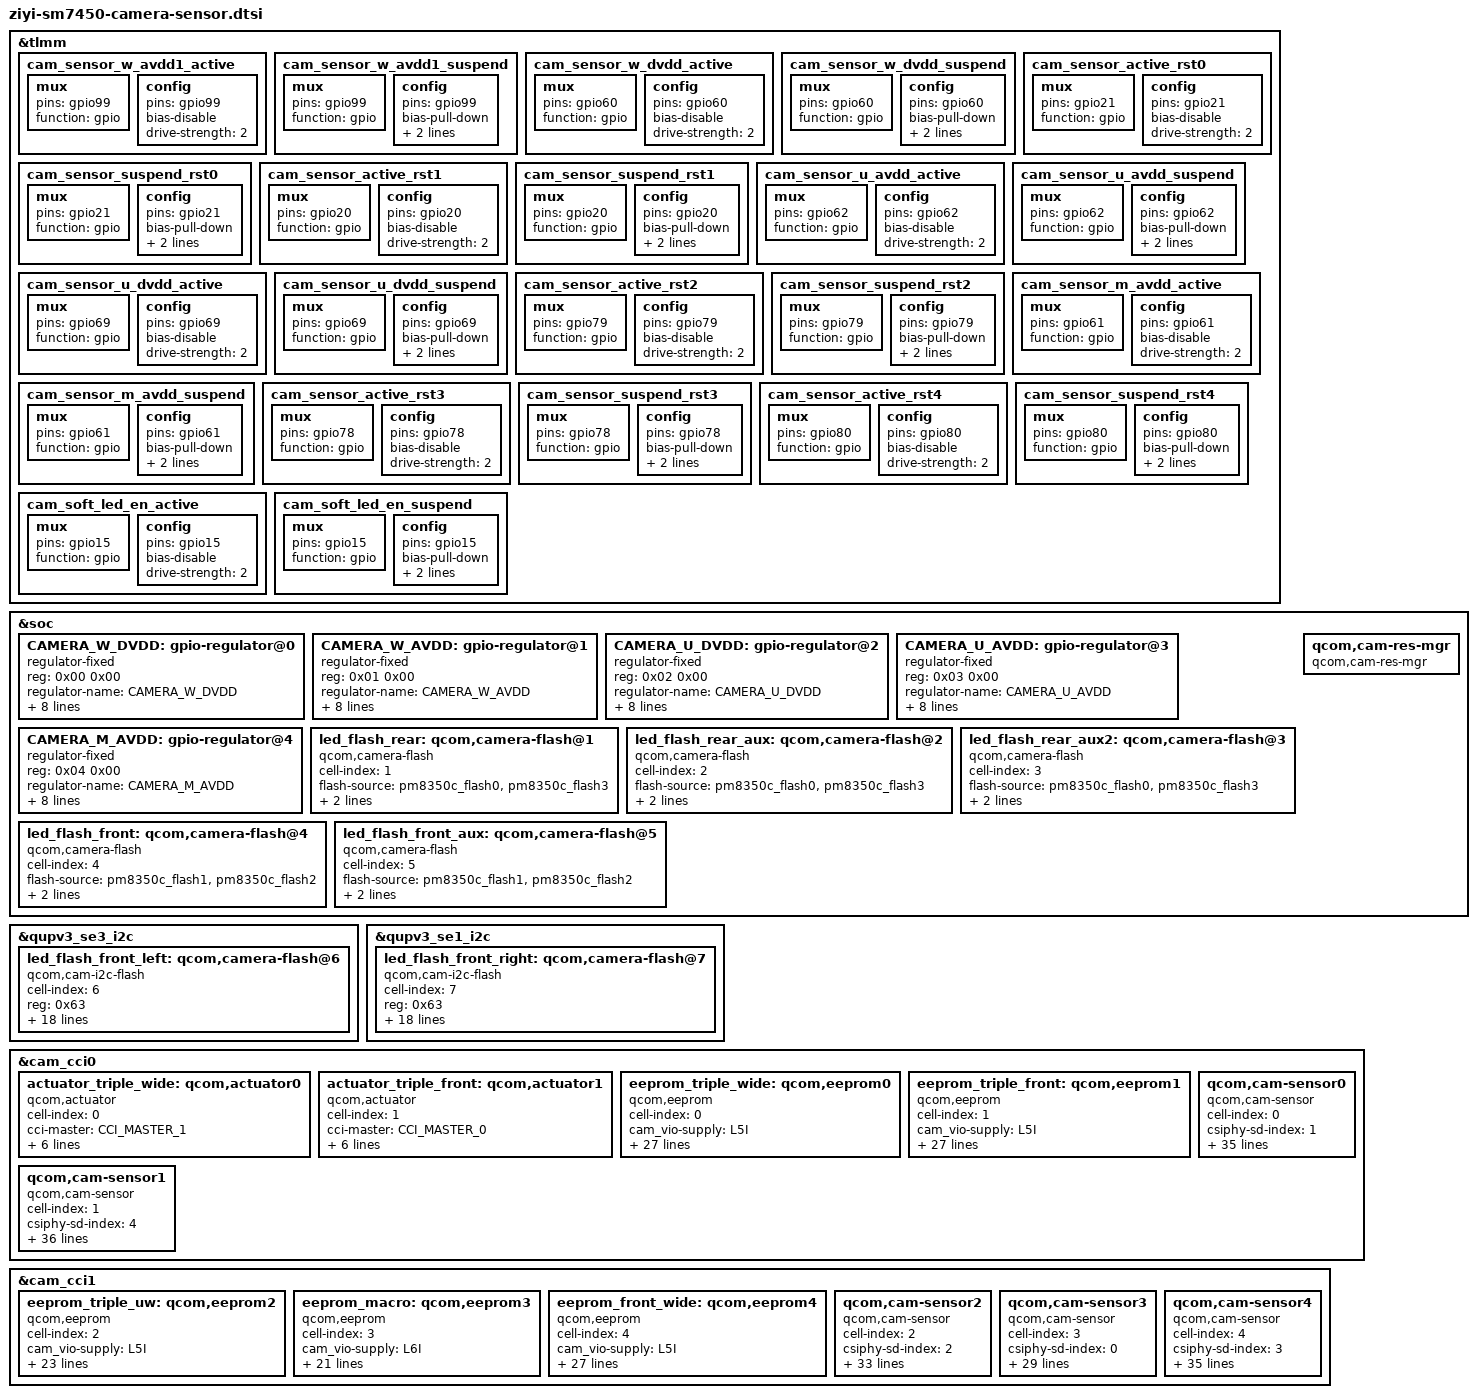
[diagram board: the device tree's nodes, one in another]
#include <dt-bindings/clock/qcom,camcc-diwali.h>
#include <dt-bindings/msm-camera.h>

&tlmm {
	//wide avdd
	cam_sensor_w_avdd1_active: cam_sensor_w_avdd1_active {
		/* SENSOR WIDE DVDD ENABLE */
		mux {
			pins = "gpio99";
			function = "gpio";
		};

		config {
			pins = "gpio99";
			bias-disable; /* No PULL */
			drive-strength = <2>; /* 2 MA */
		};
	};

	cam_sensor_w_avdd1_suspend: cam_sensor_w_avdd1_suspend {
		/* SENSOR WIDE DVDD DISABLE */
		mux {
			pins = "gpio99";
			function = "gpio";
		};

		config {
			pins = "gpio99";
			bias-pull-down; /* PULL DOWN */
			drive-strength = <2>; /* 2 MA */
			output-low;
		};
	};

	//wide dvdd
	cam_sensor_w_dvdd_active: cam_sensor_w_dvdd_active {
		/* SENSOR WIDE DVDD ENABLE */
		mux {
			pins = "gpio60";
			function = "gpio";
		};

		config {
			pins = "gpio60";
			bias-disable; /* No PULL */
			drive-strength = <2>; /* 2 MA */
		};
	};

	cam_sensor_w_dvdd_suspend: cam_sensor_w_dvdd_suspend {
		/* SENSOR WIDE DVDD DISABLE */
		mux {
			pins = "gpio60";
			function = "gpio";
		};

		config {
			pins = "gpio60";
			bias-pull-down; /* PULL DOWN */
			drive-strength = <2>; /* 2 MA */
			output-low;
		};
	};

	//wide reset
	cam_sensor_active_rst0: cam_sensor_active_rst0 {
		/* RESET FRONT */
		mux {
			pins = "gpio21";
			function = "gpio";
		};

		config {
			pins = "gpio21";
			bias-disable; /* No PULL */
			drive-strength = <2>; /* 2 MA */
		};
	};

	cam_sensor_suspend_rst0: cam_sensor_suspend_rst0 {
		/* RESET FRONT */
		mux {
			pins = "gpio21";
			function = "gpio";
		};

		config {
			pins = "gpio21";
			bias-pull-down; /* PULL DOWN */
			drive-strength = <2>; /* 2 MA */
			output-low;
		};
	};

	//front reset
	cam_sensor_active_rst1: cam_sensor_active_rst1 {
		/* RESET FRONT */
		mux {
			pins = "gpio20";
			function = "gpio";
		};

		config {
			pins = "gpio20";
			bias-disable; /* No PULL */
			drive-strength = <2>; /* 2 MA */
		};
	};

	cam_sensor_suspend_rst1: cam_sensor_suspend_rst1 {
		/* RESET FRONT */
		mux {
			pins = "gpio20";
			function = "gpio";
		};

		config {
			pins = "gpio20";
			bias-pull-down; /* PULL DOWN */
			drive-strength = <2>; /* 2 MA */
			output-low;
		};
	};

	//ultra avdd
	cam_sensor_u_avdd_active: cam_sensor_u_avdd_active {
		/* SENSOR ULTRA AVDD ENABLE */
		mux {
			pins = "gpio62";
			function = "gpio";
		};

		config {
			pins = "gpio62";
			bias-disable; /* No PULL */
			drive-strength = <2>; /* 2 MA */
		};
	};

	cam_sensor_u_avdd_suspend: cam_sensor_u_avdd_suspend {
		/* SENSOR ULTRA AVDD DISABLE */
		mux {
			pins = "gpio62";
			function = "gpio";
		};

		config {
			pins = "gpio62";
			bias-pull-down; /* PULL DOWN */
			drive-strength = <2>; /* 2 MA */
			output-low;
		};
	};

	//ultra dvdd
	cam_sensor_u_dvdd_active: cam_sensor_u_dvdd_active {
		/* SENSOR ULTRA DVDD ENABLE */
		mux {
			pins = "gpio69";
			function = "gpio";
		};

		config {
			pins = "gpio69";
			bias-disable; /* No PULL */
			drive-strength = <2>; /* 2 MA */
		};
	};

	cam_sensor_u_dvdd_suspend: cam_sensor_u_dvdd_suspend {
		/* SENSOR ULTRA DVDD DISABLE */
		mux {
			pins = "gpio69";
			function = "gpio";
		};

		config {
			pins = "gpio69";
			bias-pull-down; /* PULL DOWN */
			drive-strength = <2>; /* 2 MA */
			output-low;
		};
	};

	//ultra reset
	cam_sensor_active_rst2: cam_sensor_active_rst2 {
		/* RESET ULTRA */
		mux {
			pins = "gpio79";
			function = "gpio";
		};

		config {
			pins = "gpio79";
			bias-disable; /* No PULL */
			drive-strength = <2>; /* 2 MA */
		};
	};

	cam_sensor_suspend_rst2: cam_sensor_suspend_rst2 {
		/* RESET ULTRA */
		mux {
			pins = "gpio79";
			function = "gpio";
		};

		config {
			pins = "gpio79";
			bias-pull-down; /* PULL DOWN */
			drive-strength = <2>; /* 2 MA */
			output-low;
		};
	};

	//macro avdd
	cam_sensor_m_avdd_active: cam_sensor_m_avdd_active {
		/* SENSOR MACRO AVDD ENABLE */
		mux {
			pins = "gpio61";
			function = "gpio";
		};

		config {
			pins = "gpio61";
			bias-disable; /* No PULL */
			drive-strength = <2>; /* 2 MA */
		};
	};

	cam_sensor_m_avdd_suspend: cam_sensor_m_avdd_suspend {
		/* SENSOR MACRO AVDD DISABLE */
		mux {
			pins = "gpio61";
			function = "gpio";
		};

		config {
			pins = "gpio61";
			bias-pull-down; /* PULL DOWN */
			drive-strength = <2>; /* 2 MA */
			output-low;
		};
	};

	//macro reset
	cam_sensor_active_rst3: cam_sensor_active_rst3 {
		/* RESET MACRO */
		mux {
			pins = "gpio78";
			function = "gpio";
		};

		config {
			pins = "gpio78";
			bias-disable; /* No PULL */
			drive-strength = <2>; /* 2 MA */
		};
	};

	cam_sensor_suspend_rst3: cam_sensor_suspend_rst3 {
		/* RESET MACRO */
		mux {
			pins = "gpio78";
			function = "gpio";
		};

		config {
			pins = "gpio78";
			bias-pull-down; /* PULL DOWN */
			drive-strength = <2>; /* 2 MA */
			output-low;
		};
	};


	//front ultra reset
	cam_sensor_active_rst4: cam_sensor_active_rst4 {
		/* RESET FRONT ULTRA*/
		mux {
			pins = "gpio80";
			function = "gpio";
		};

		config {
			pins = "gpio80";
			bias-disable; /* No PULL */
			drive-strength = <2>; /* 2 MA */
		};
	};

	cam_sensor_suspend_rst4: cam_sensor_suspend_rst4 {
		/* RESET FRONT ULTRA*/
		mux {
			pins = "gpio80";
			function = "gpio";
		};

		config {
			pins = "gpio80";
			bias-pull-down; /* PULL DOWN */
			drive-strength = <2>; /* 2 MA */
			output-low;
		};
	};

	//soft flash control
	cam_soft_led_en_active: cam_soft_led_en_active {
		mux {
			pins = "gpio15";
			function = "gpio";
		};

		config {
			pins = "gpio15";
			bias-disable; /* No PULL */
			drive-strength = <2>; /* 2 MA */
		};
	};
	cam_soft_led_en_suspend: cam_soft_led_en_suspend {
		mux {
			pins = "gpio15";
			function = "gpio";
		};

		config {
			pins = "gpio15";
			bias-pull-down; /* PULL DOWN */
			drive-strength = <2>; /* 2 MA */
			output-low;
		};
	};
};


&soc {
	CAMERA_W_DVDD: gpio-regulator@0 {
		compatible = "regulator-fixed";
		reg = <0x00 0x00>;
		regulator-name = "CAMERA_W_DVDD";
		regulator-min-microvolt = <1100000>;
		regulator-max-microvolt = <1100000>;
		regulator-enable-ramp-delay = <100>;
		enable-active-high;
		gpio = <&tlmm 60 0>;
		pinctrl-names = "default", "sleep";
		pinctrl-0 = <&cam_sensor_w_dvdd_active &cam_sensor_w_dvdd_suspend>;
		vin-supply = <&S8B>;
	};

	CAMERA_W_AVDD: gpio-regulator@1 {
		compatible = "regulator-fixed";
		reg = <0x01 0x00>;
		regulator-name = "CAMERA_W_AVDD";
		regulator-min-microvolt = <2800000>;
		regulator-max-microvolt = <2800000>;
		regulator-enable-ramp-delay = <100>;
		enable-active-high;
		gpio = <&tlmm 99 0>;
		pinctrl-names = "default", "sleep";
		pinctrl-0 = <&cam_sensor_w_avdd1_active &cam_sensor_w_avdd1_suspend>;
		vin-supply = <&BOB>;
	};

	CAMERA_U_DVDD: gpio-regulator@2 {
		compatible = "regulator-fixed";
		reg = <0x02 0x00>;
		regulator-name = "CAMERA_U_DVDD";
		regulator-min-microvolt = <1050000>;
		regulator-max-microvolt = <1050000>;
		regulator-enable-ramp-delay = <100>;
		enable-active-high;
		gpio = <&tlmm 69 0>;
		pinctrl-names = "default", "sleep";
		pinctrl-0 = <&cam_sensor_u_dvdd_active &cam_sensor_u_dvdd_suspend>;
		vin-supply = <&S8B>;
	};

	CAMERA_U_AVDD: gpio-regulator@3 {
		compatible = "regulator-fixed";
		reg = <0x03 0x00>;
		regulator-name = "CAMERA_U_AVDD";
		regulator-min-microvolt = <2800000>;
		regulator-max-microvolt = <2800000>;
		regulator-enable-ramp-delay = <100>;
		enable-active-high;
		gpio = <&tlmm 62 0>;
		pinctrl-names = "default", "sleep";
		pinctrl-0 = <&cam_sensor_u_avdd_active &cam_sensor_u_avdd_suspend>;
		vin-supply = <&BOB>;
	};

	CAMERA_M_AVDD: gpio-regulator@4 {
		compatible = "regulator-fixed";
		reg = <0x04 0x00>;
		regulator-name = "CAMERA_M_AVDD";
		regulator-min-microvolt = <2800000>;
		regulator-max-microvolt = <2800000>;
		regulator-enable-ramp-delay = <100>;
		enable-active-high;
		gpio = <&tlmm 61 0>;
		pinctrl-names = "default", "sleep";
		pinctrl-0 = <&cam_sensor_m_avdd_active &cam_sensor_m_avdd_suspend>;
		vin-supply = <&BOB>;
	};

	led_flash_rear: qcom,camera-flash@1 {
		cell-index = <1>;
		compatible = "qcom,camera-flash";
		flash-source = <&pm8350c_flash0 &pm8350c_flash3>;
		torch-source = <&pm8350c_torch0 &pm8350c_torch3>;
		switch-source = <&pm8350c_switch0>;
		status = "ok";
	};

	led_flash_rear_aux: qcom,camera-flash@2 {
		cell-index = <2>;
		compatible = "qcom,camera-flash";
		flash-source = <&pm8350c_flash0 &pm8350c_flash3>;
		torch-source = <&pm8350c_torch0 &pm8350c_torch3>;
		switch-source = <&pm8350c_switch0>;
		status = "ok";
	};

	led_flash_rear_aux2: qcom,camera-flash@3 {
		cell-index = <3>;
		compatible = "qcom,camera-flash";
		flash-source = <&pm8350c_flash0 &pm8350c_flash3>;
		torch-source = <&pm8350c_torch0 &pm8350c_torch3>;
		switch-source = <&pm8350c_switch0>;
		status = "ok";
	};

	led_flash_front: qcom,camera-flash@4 {
		cell-index = <4>;
		compatible = "qcom,camera-flash";
		flash-source = <&pm8350c_flash1 &pm8350c_flash2>;
		torch-source = <&pm8350c_torch1 &pm8350c_torch2>;
		switch-source = <&pm8350c_switch1>;
		status = "ok";
	};

	led_flash_front_aux: qcom,camera-flash@5 {
		cell-index = <5>;
		compatible = "qcom,camera-flash";
		flash-source = <&pm8350c_flash1 &pm8350c_flash2>;
		torch-source = <&pm8350c_torch1 &pm8350c_torch2>;
		switch-source = <&pm8350c_switch1>;
		status = "ok";
	};

	qcom,cam-res-mgr {
		compatible = "qcom,cam-res-mgr";
		status = "ok";
	};
};

&qupv3_se3_i2c {
	status = "ok";
	led_flash_front_left: qcom,camera-flash@6 {
		cell-index = <6>;
		reg = <0x63>;
		qcom,slave-id = <0x63>;
		compatible = "qcom,cam-i2c-flash";
		qcom,flash-name = "cam-i2c-flash";
		flash-type = <1>;
		cam_vio-supply = <&L18B>;
		cam_bob-supply = <&BOB>;
		regulator-names = "cam_vio","cam_bob";
		rgltr-cntrl-support;
		rgltr-min-voltage = <1800000 3008000>;
		rgltr-max-voltage = <1800000 3960000>;
		rgltr-load-current = <1067000 7840000>;
		qcom,gpio-no-mux = <0>;
		pinctrl-names = "cam_default", "cam_suspend";
		pinctrl-0 = <&cam_soft_led_en_active>;
		pinctrl-1 = <&cam_soft_led_en_suspend>;
		gpios = <&tlmm 15 0>;
		gpio-custom1 = <0>;
		gpio-req-tbl-num = <0>;
		gpio-req-tbl-flags = <0>;
		gpio-req-tbl-label = "CUSTOM_GPIO1";
		status = "ok";
	};
};

&qupv3_se1_i2c {
	status = "ok";
	led_flash_front_right: qcom,camera-flash@7 {
		cell-index = <7>;
		reg = <0x63>;
		qcom,slave-id = <0x63>;
		compatible = "qcom,cam-i2c-flash";
		qcom,flash-name = "cam-i2c-flash";
		flash-type = <1>;
		cam_vio-supply = <&L18B>;
		cam_bob-supply = <&BOB>;
		regulator-names = "cam_vio","cam_bob";
		rgltr-cntrl-support;
		rgltr-min-voltage = <1800000 3008000>;
		rgltr-max-voltage = <1800000 3960000>;
		rgltr-load-current = <1067000 7840000>;
		qcom,gpio-no-mux = <0>;
		pinctrl-names = "cam_default", "cam_suspend";
		pinctrl-0 = <&cam_soft_led_en_active>;
		pinctrl-1 = <&cam_soft_led_en_suspend>;
		gpios = <&tlmm 15 0>;
		gpio-custom1 = <0>;
		gpio-req-tbl-num = <0>;
		gpio-req-tbl-flags = <0>;
		gpio-req-tbl-label = "CUSTOM_GPIO1";
		status = "ok";
	};
};

&cam_cci0 {
	actuator_triple_wide: qcom,actuator0 {
		cell-index = <0>;
		compatible = "qcom,actuator";
		cci-master = <CCI_MASTER_1>;
		cam_vaf-supply = <&L6C>;
		regulator-names = "cam_vaf";
		rgltr-cntrl-support;
		rgltr-min-voltage = <2800000>;
		rgltr-max-voltage = <2800000>;
		rgltr-load-current = <300000>;
	};

	actuator_triple_front: qcom,actuator1 {
		cell-index = <1>;
		compatible = "qcom,actuator";
		cci-master = <CCI_MASTER_0>;
		cam_vaf-supply = <&L9C>;
		regulator-names = "cam_vaf";
		rgltr-cntrl-support;
		rgltr-min-voltage = <2800000>;
		rgltr-max-voltage = <2800000>;
		rgltr-load-current = <120000>;
	};

	eeprom_triple_wide: qcom,eeprom0 {
		cell-index = <0>;
		compatible = "qcom,eeprom";
		cam_vio-supply = <&L5I>;
		cam_vana-supply = <&CAMERA_W_AVDD>;
		cam_vdig-supply = <&CAMERA_W_DVDD>;
		cam_vaf-supply = <&L6C>;
		cam_clk-supply = <&cam_cc_titan_top_gdsc>;
		regulator-names = "cam_vio", "cam_vana", "cam_vdig",
			"cam_clk", "cam_vaf";
		rgltr-cntrl-support;
		rgltr-min-voltage = <1800000 2704000 1100000 2800000 0>;
		rgltr-max-voltage = <1800000 2896000 1100000 2800000 0>;
		rgltr-load-current = <3500 164100 1251000 300000 0>;
		gpio-no-mux = <0>;
		pinctrl-names = "cam_default", "cam_suspend";
		pinctrl-0 = <&cam_sensor_mclk1_active
				 &cam_sensor_active_rst0>;
		pinctrl-1 = <&cam_sensor_mclk1_suspend
				 &cam_sensor_suspend_rst0>;
		gpios = <&tlmm 65 0>,
			<&tlmm 21 0>;
		gpio-reset = <1>;
		gpio-req-tbl-num = <0 1>;
		gpio-req-tbl-flags = <1 0>;
		gpio-req-tbl-label = "CAMIF_MCLK1",
					"CAM_RESET0";
		cci-master = <CCI_MASTER_1>;
		clocks = <&camcc CAM_CC_MCLK1_CLK>;
		clock-names = "cam_clk";
		clock-cntl-level = "nominal";
		clock-rates = <19200000>;
		status = "ok";
	};

	eeprom_triple_front: qcom,eeprom1 {
		cell-index = <1>;
		compatible = "qcom,eeprom";
		cam_vio-supply = <&L5I>;
		cam_vana-supply = <&L4I>;
		cam_vdig-supply = <&L1I>;
		cam_vaf-supply = <&L9C>;
		cam_clk-supply = <&cam_cc_titan_top_gdsc>;
		regulator-names = "cam_vio", "cam_vana", "cam_vdig",
			"cam_clk", "cam_vaf";
		rgltr-cntrl-support;
		rgltr-min-voltage = <1800000 2704000 1000000 2800000 0>;
		rgltr-max-voltage = <1800000 2896000 1000000 2800000 0>;
		rgltr-load-current = <3500 164100 1251000 300000 0>;
		gpio-no-mux = <0>;
		pinctrl-names = "cam_default", "cam_suspend";
		pinctrl-0 = <&cam_sensor_mclk0_active
				 &cam_sensor_active_rst1>;
		pinctrl-1 = <&cam_sensor_mclk0_suspend
				 &cam_sensor_suspend_rst1>;
		gpios = <&tlmm 64 0>,
			<&tlmm 20 0>;
		gpio-reset = <1>;
		gpio-req-tbl-num = <0 1>;
		gpio-req-tbl-flags = <1 0>;
		gpio-req-tbl-label = "CAMIF_MCLK0",
					"CAM_RESET1";
		cci-master = <CCI_MASTER_0>;
		clocks = <&camcc CAM_CC_MCLK0_CLK>;
		clock-names = "cam_clk";
		clock-cntl-level = "nominal";
		clock-rates = <19200000>;
		status = "ok";
	};

	qcom,cam-sensor0 {
		cell-index = <0>;
		compatible = "qcom,cam-sensor";
		csiphy-sd-index = <1>;
		sensor-position-roll = <90>;
		sensor-position-pitch = <0>;
		sensor-position-yaw = <180>;
		eeprom-src = <&eeprom_triple_wide>;
		actuator-src = <&actuator_triple_wide>;
		led-flash-src = <&led_flash_rear>;
		cam_vio-supply = <&L5I>;
		cam_vana-supply = <&CAMERA_W_AVDD>;
		cam_vdig-supply = <&CAMERA_W_DVDD>;
		cam_vaf-supply = <&L6C>;
		cam_clk-supply = <&cam_cc_titan_top_gdsc>;
		cam_bob-supply = <&BOB>;
		regulator-names = "cam_vio", "cam_vana", "cam_vdig",
			"cam_vaf", "cam_clk", "cam_bob";
		rgltr-cntrl-support;
		rgltr-min-voltage = <1800000 2704000 1100000 2800000 0 3008000>;
		rgltr-max-voltage = <1800000 2896000 1100000 2800000 0 3960000>;
		rgltr-load-current = <3500 164100 1251000 300000 0 7840000>;
		gpio-no-mux = <0>;
		pinctrl-names = "cam_default", "cam_suspend";
		pinctrl-0 = <&cam_sensor_mclk1_active
				 &cam_sensor_active_rst0>;
		pinctrl-1 = <&cam_sensor_mclk1_suspend
				 &cam_sensor_suspend_rst0>;
		gpios = <&tlmm 65 0>,
			<&tlmm 21 0>;
		gpio-reset = <1>;
		gpio-req-tbl-num = <0 1>;
		gpio-req-tbl-flags = <1 0>;
		gpio-req-tbl-label = "CAMIF_MCLK1",
					"CAM_RESET0";
		cci-master = <CCI_MASTER_1>;
		clocks = <&camcc CAM_CC_MCLK1_CLK>;
		clock-names = "cam_clk";
		clock-cntl-level = "nominal";
		clock-rates = <19200000>;
		status = "ok";
	};

	qcom,cam-sensor1 {
		cell-index = <1>;
		compatible = "qcom,cam-sensor";
		csiphy-sd-index = <4>;
		sensor-position-roll = <270>;
		sensor-position-pitch = <0>;
		sensor-position-yaw = <0>;
		eeprom-src = <&eeprom_triple_front>;
		actuator-src = <&actuator_triple_front>;
		led-flash-src = <&led_flash_front_right>;
		led-flash-src-gl = <&led_flash_front>;
		cam_vio-supply = <&L5I>;
		cam_vana-supply = <&L4I>;
		cam_vdig-supply = <&L1I>;
		cam_vaf-supply = <&L9C>;
		cam_clk-supply = <&cam_cc_titan_top_gdsc>;
		cam_bob-supply = <&BOB>;
		regulator-names = "cam_vio", "cam_vana", "cam_vdig",
			"cam_vaf", "cam_clk", "cam_bob";
		rgltr-cntrl-support;
		rgltr-min-voltage = <1800000 2800000 1000000 2800000 0 3008000>;
		rgltr-max-voltage = <1800000 2800000 1000000 2800000 0 3960000>;
		rgltr-load-current = <15000 55200 469000 120000 0 7840000>;
		gpio-no-mux = <0>;
		pinctrl-names = "cam_default", "cam_suspend";
		pinctrl-0 = <&cam_sensor_mclk0_active
				 &cam_sensor_active_rst1>;
		pinctrl-1 = <&cam_sensor_mclk0_suspend
				 &cam_sensor_suspend_rst1>;
		gpios = <&tlmm 64 0>,
			<&tlmm 20 0>;
		gpio-reset = <1>;
		gpio-req-tbl-num = <0 1>;
		gpio-req-tbl-flags = <1 0>;
		gpio-req-tbl-label = "CAMIF_MCLK0",
					"CAM_RESET1";
		cci-master = <CCI_MASTER_0>;
		clocks = <&camcc CAM_CC_MCLK0_CLK>;
		clock-names = "cam_clk";
		clock-cntl-level = "nominal";
		clock-rates = <19200000>;
		status = "ok";
	};
};

&cam_cci1 {
	eeprom_triple_uw: qcom,eeprom2 {
		cell-index = <2>;
		compatible = "qcom,eeprom";
		cam_vio-supply = <&L5I>;
		cam_vana-supply = <&CAMERA_U_AVDD>;
		cam_vdig-supply = <&CAMERA_U_DVDD>;
		cam_clk-supply = <&cam_cc_titan_top_gdsc>;
		regulator-names = "cam_vio", "cam_vana",
			"cam_vdig", "cam_clk";
		rgltr-cntrl-support;
		rgltr-min-voltage = <1800000 2800000 1050000 0>;
		rgltr-max-voltage = <1800000 2800000 1050000 0>;
		rgltr-load-current = <3500 29500 148700 0>;
		gpio-no-mux = <0>;
		pinctrl-names = "cam_default", "cam_suspend";
		pinctrl-0 = <&cam_sensor_mclk3_active
				&cam_sensor_active_rst2>;
		pinctrl-1 = <&cam_sensor_mclk3_suspend
				&cam_sensor_suspend_rst2>;
		gpios = <&tlmm 67 0>,
			<&tlmm 79 0>;
		gpio-reset = <1>;
		gpio-req-tbl-num = <0 1>;
		gpio-req-tbl-flags = <1 0>;
		gpio-req-tbl-label = "CAMIF_MCLK3",
					"CAM_RESET2";
		cci-master = <CCI_MASTER_1>;
		clocks = <&camcc CAM_CC_MCLK3_CLK>;
		clock-names = "cam_clk";
		clock-cntl-level = "nominal";
		clock-rates = <19200000>;
		status = "ok";
	};

	eeprom_macro: qcom,eeprom3 {
		cell-index = <3>;
		compatible = "qcom,eeprom";
		cam_vio-supply = <&L6I>;
		cam_vana-supply = <&CAMERA_M_AVDD>;
		cam_clk-supply = <&cam_cc_titan_top_gdsc>;
		regulator-names = "cam_vio", "cam_vana", "cam_clk";
		rgltr-cntrl-support;
		rgltr-min-voltage = <1800000 2800000 0>;
		rgltr-max-voltage = <1800000 2800000 0>;
		rgltr-load-current = <70000 40000 0>;
		gpio-no-mux = <0>;
		pinctrl-names = "cam_default", "cam_suspend";
		pinctrl-0 = <&cam_sensor_mclk2_active
				 &cam_sensor_active_rst3>;
		pinctrl-1 = <&cam_sensor_mclk2_suspend
				 &cam_sensor_suspend_rst3>;
		gpios = <&tlmm 66 0>,
			<&tlmm 78 0>;
		gpio-reset = <1>;
		gpio-req-tbl-num = <0 1>;
		gpio-req-tbl-flags = <1 0>;
		gpio-req-tbl-label = "CAMIF_MCLK2",
					"CAM_RESET3";
		cci-master = <CCI_MASTER_0>;
		clocks = <&camcc CAM_CC_MCLK2_CLK>;
		clock-names = "cam_clk";
		clock-cntl-level = "nominal";
		clock-rates = <19200000>;
		status = "ok";
	};

	eeprom_front_wide: qcom,eeprom4 {
		cell-index = <4>;
		compatible = "qcom,eeprom";
		cam_vio-supply = <&L5I>;
		cam_vana-supply = <&L3I>;
		cam_vdig-supply = <&L2I>;
		cam_v_custom1-supply = <&L2I>;
		cam_clk-supply = <&cam_cc_titan_top_gdsc>;
		regulator-names = "cam_vio", "cam_vana", "cam_vdig","cam_v_custom1",
			"cam_clk";
		rgltr-cntrl-support;
		rgltr-min-voltage = <1800000 2800000 1000000 1200000 0>;
		rgltr-max-voltage = <1800000 2800000 1000000 1200000 0>;
		rgltr-load-current = <15000 55200 469000 469000 0>;
		gpio-no-mux = <0>;
		pinctrl-names = "cam_default", "cam_suspend";
		pinctrl-0 = <&cam_sensor_mclk4_active
				 &cam_sensor_active_rst4>;
		pinctrl-1 = <&cam_sensor_mclk4_suspend
				 &cam_sensor_suspend_rst4>;
		gpios = <&tlmm 68 0>,
			<&tlmm 80 0>;
		gpio-reset = <1>;
		gpio-req-tbl-num = <0 1>;
		gpio-req-tbl-flags = <1 0>;
		gpio-req-tbl-label = "CAMIF_MCLK4",
					"CAM_RESET4";
		cci-master = <CCI_MASTER_1>;
		clocks = <&camcc CAM_CC_MCLK4_CLK>;
		clock-names = "cam_clk";
		clock-cntl-level = "nominal";
		clock-rates = <19200000>;
		status = "ok";
	};

	qcom,cam-sensor2 {
		cell-index = <2>;
		compatible = "qcom,cam-sensor";
		csiphy-sd-index = <2>;
		sensor-position-roll = <90>;
		sensor-position-pitch = <0>;
		sensor-position-yaw = <180>;
		eeprom-src = <&eeprom_triple_uw>;
		led-flash-src = <&led_flash_rear_aux>;
		cam_vio-supply = <&L5I>;
		cam_vana-supply = <&CAMERA_U_AVDD>;
		cam_vdig-supply = <&CAMERA_U_DVDD>;
		cam_clk-supply = <&cam_cc_titan_top_gdsc>;
		cam_bob-supply = <&BOB>;
		regulator-names = "cam_vio", "cam_vana",
			"cam_vdig", "cam_clk", "cam_bob";
		rgltr-cntrl-support;
		rgltr-min-voltage = <1800000 2800000 1050000 0 3008000>;
		rgltr-max-voltage = <1800000 2800000 1050000 0 3960000>;
		rgltr-load-current = <3500 29500 148700 0 7840000>;
		gpio-no-mux = <0>;
		pinctrl-names = "cam_default", "cam_suspend";
		pinctrl-0 = <&cam_sensor_mclk3_active
				&cam_sensor_active_rst2>;
		pinctrl-1 = <&cam_sensor_mclk3_suspend
				&cam_sensor_suspend_rst2>;
		gpios = <&tlmm 67 0>,
			<&tlmm 79 0>;
		gpio-reset = <1>;
		gpio-req-tbl-num = <0 1>;
		gpio-req-tbl-flags = <1 0>;
		gpio-req-tbl-label = "CAMIF_MCLK3",
					"CAM_RESET2";
		cci-master = <CCI_MASTER_1>;
		clocks = <&camcc CAM_CC_MCLK3_CLK>;
		clock-names = "cam_clk";
		clock-cntl-level = "nominal";
		clock-rates = <19200000>;
		status = "ok";
	};

	qcom,cam-sensor3 {
		cell-index = <3>;
		compatible = "qcom,cam-sensor";
		csiphy-sd-index = <0>;
		sensor-position-roll = <90>;
		sensor-position-pitch = <0>;
		sensor-position-yaw = <180>;
		eeprom-src = <&eeprom_macro>;
		led-flash-src = <&led_flash_rear_aux2>;
		cam_vio-supply = <&L6I>;
		cam_vana-supply = <&CAMERA_M_AVDD>;
		cam_clk-supply = <&cam_cc_titan_top_gdsc>;
		cam_bob-supply = <&BOB>;
		regulator-names = "cam_vio", "cam_vana",
			"cam_clk", "cam_bob";
		rgltr-cntrl-support;
		rgltr-min-voltage = <1800000 2800000 0 3008000>;
		rgltr-max-voltage = <1800000 2800000 0 3960000>;
		rgltr-load-current = <70000 40000 0 7840000>;
		gpio-no-mux = <0>;
		pinctrl-names = "cam_default", "cam_suspend";
		pinctrl-0 = <&cam_sensor_mclk2_active
				 &cam_sensor_active_rst3>;
		pinctrl-1 = <&cam_sensor_mclk2_suspend
				 &cam_sensor_suspend_rst3>;
		gpios = <&tlmm 66 0>,
			<&tlmm 78 0>;
		gpio-reset = <1>;
		gpio-req-tbl-num = <0 1>;
		gpio-req-tbl-flags = <1 0>;
		gpio-req-tbl-label = "CAMIF_MCLK2",
					"CAM_RESET3";
		cci-master = <CCI_MASTER_0>;
		clocks = <&camcc CAM_CC_MCLK2_CLK>;
		clock-names = "cam_clk";
		clock-cntl-level = "nominal";
		clock-rates = <19200000>;
		status = "ok";
	};

	qcom,cam-sensor4 {
		cell-index = <4>;
		compatible = "qcom,cam-sensor";
		csiphy-sd-index = <3>;
		sensor-position-roll = <270>;
		sensor-position-pitch = <0>;
		sensor-position-yaw = <0>;
		eeprom-src = <&eeprom_front_wide>;
		//actuator-src = <&actuator_triple_tele>;
		led-flash-src = <&led_flash_front_left>;
		led-flash-src-gl = <&led_flash_front_aux>;
		cam_vio-supply = <&L5I>;
		cam_vana-supply = <&L3I>;
		cam_vdig-supply = <&L2I>;
		cam_v_custom1-supply = <&L2I>;
		cam_clk-supply = <&cam_cc_titan_top_gdsc>;
		cam_bob-supply = <&BOB>;
		regulator-names = "cam_vio", "cam_vana", "cam_vdig","cam_v_custom1",
			"cam_clk", "cam_bob";
		rgltr-cntrl-support;
		rgltr-min-voltage = <1800000 2800000 1000000 1200000 0 3008000>;
		rgltr-max-voltage = <1800000 2800000 1000000 1200000 0 3960000>;
		rgltr-load-current = <15000 55200 469000 469000 0 7840000>;
		gpio-no-mux = <0>;
		pinctrl-names = "cam_default", "cam_suspend";
		pinctrl-0 = <&cam_sensor_mclk4_active
				 &cam_sensor_active_rst4>;
		pinctrl-1 = <&cam_sensor_mclk4_suspend
				 &cam_sensor_suspend_rst4>;
		gpios = <&tlmm 68 0>,
			<&tlmm 80 0>;
		gpio-reset = <1>;
		gpio-req-tbl-num = <0 1>;
		gpio-req-tbl-flags = <1 0>;
		gpio-req-tbl-label = "CAMIF_MCLK4",
					"CAM_RESET4";
		cci-master = <CCI_MASTER_1>;
		clocks = <&camcc CAM_CC_MCLK4_CLK>;
		clock-names = "cam_clk";
		clock-cntl-level = "nominal";
		clock-rates = <19200000>;
		status = "ok";
	};
};
